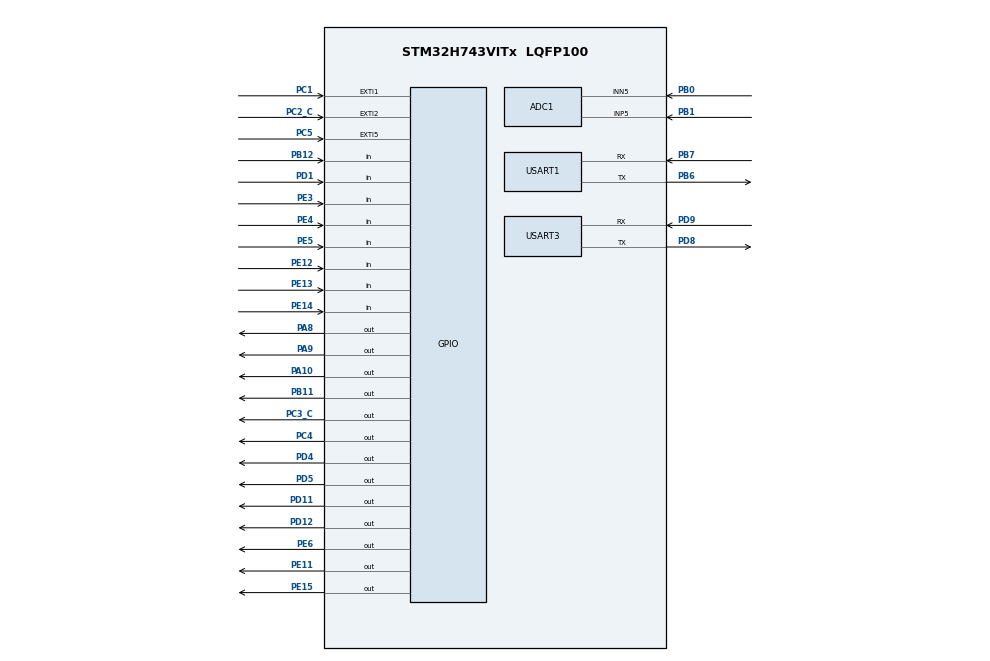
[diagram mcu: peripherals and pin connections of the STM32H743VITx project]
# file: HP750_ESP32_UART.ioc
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ADC1.Channel-1\#ChannelRegularConversion=ADC_CHANNEL_5
ADC1.NbrOfConversionFlag=1
ADC1.OffsetNumber-1\#ChannelRegularConversion=ADC_OFFSET_NONE
ADC1.OffsetSignedSaturation-1\#ChannelRegularConversion=DISABLE
ADC1.Rank-1\#ChannelRegularConversion=1
ADC1.SamplingTime-1\#ChannelRegularConversion=ADC_SAMPLETIME_1CYCLE_5
ADC1.SingleDiff-1\#ChannelRegularConversion=ADC_DIFFERENTIAL_ENDED
ADC1.master=1
Dma.Request0=USART3_RX
Dma.Request1=USART1_RX
Dma.USART1_RX.1.Direction=DMA_PERIPH_TO_MEMORY
Dma.USART1_RX.1.EventEnable=DISABLE
Dma.USART1_RX.1.FIFOMode=DMA_FIFOMODE_DISABLE
Dma.USART1_RX.1.Instance=DMA1_Stream1
Dma.USART1_RX.1.MemDataAlignment=DMA_MDATAALIGN_BYTE
Dma.USART1_RX.1.MemInc=DMA_MINC_ENABLE
Dma.USART1_RX.1.Mode=DMA_NORMAL
Dma.USART1_RX.1.PeriphDataAlignment=DMA_PDATAALIGN_BYTE
Dma.USART1_RX.1.PeriphInc=DMA_PINC_DISABLE
Dma.USART1_RX.1.Polarity=HAL_DMAMUX_REQ_GEN_RISING
Dma.USART1_RX.1.Priority=DMA_PRIORITY_LOW
Dma.USART1_RX.1.RequestNumber=1
Dma.USART1_RX.1.SignalID=NONE
Dma.USART1_RX.1.SyncEnable=DISABLE
Dma.USART1_RX.1.SyncPolarity=HAL_DMAMUX_SYNC_NO_EVENT
Dma.USART1_RX.1.SyncRequestNumber=1
Dma.USART1_RX.1.SyncSignalID=NONE
Dma.USART3_RX.0.Direction=DMA_PERIPH_TO_MEMORY
Dma.USART3_RX.0.EventEnable=DISABLE
Dma.USART3_RX.0.FIFOMode=DMA_FIFOMODE_DISABLE
Dma.USART3_RX.0.Instance=DMA1_Stream0
Dma.USART3_RX.0.MemDataAlignment=DMA_MDATAALIGN_BYTE
Dma.USART3_RX.0.MemInc=DMA_MINC_ENABLE
Dma.USART3_RX.0.Mode=DMA_NORMAL
Dma.USART3_RX.0.PeriphDataAlignment=DMA_PDATAALIGN_BYTE
Dma.USART3_RX.0.PeriphInc=DMA_PINC_DISABLE
Dma.USART3_RX.0.Polarity=HAL_DMAMUX_REQ_GEN_RISING
Dma.USART3_RX.0.Priority=DMA_PRIORITY_LOW
Dma.USART3_RX.0.RequestNumber=1
Dma.USART3_RX.0.SignalID=NONE
Dma.USART3_RX.0.SyncEnable=DISABLE
Dma.USART3_RX.0.SyncPolarity=HAL_DMAMUX_SYNC_NO_EVENT
Dma.USART3_RX.0.SyncRequestNumber=1
Dma.USART3_RX.0.SyncSignalID=NONE
Mcu.Family=STM32H7
Mcu.Name=STM32H743VITx
Mcu.Package=LQFP100
NVIC.DMA1_Stream0_IRQn=true\:0\:0\:false\:false\:true\:false\:true\:true
NVIC.DMA1_Stream1_IRQn=true\:0\:0\:false\:false\:true\:false\:true\:true
NVIC.PriorityGroup=NVIC_PRIORITYGROUP_4
NVIC.TIM1_UP_IRQn=true\:15\:0\:false\:false\:true\:false\:true\:true
NVIC.TimeBase=TIM1_UP_IRQn
NVIC.TimeBaseIP=TIM1
PA10.Signal=GPIO_Output
PA13\ (JTMS/SWDIO).Mode=Serial_Wire
PA13\ (JTMS/SWDIO).Signal=DEBUG_JTMS-SWDIO
PA14\ (JTCK/SWCLK).Mode=Serial_Wire
PA14\ (JTCK/SWCLK).Signal=DEBUG_JTCK-SWCLK
PA8.Signal=GPIO_Output
PA9.Signal=GPIO_Output
PB0.Signal=ADCx_INN5
PB1.Signal=ADCx_INP5
PB11.Signal=GPIO_Output
PB12.Signal=GPIO_Input
PB6.Mode=Asynchronous
PB6.Signal=USART1_TX
PB7.Mode=Asynchronous
PB7.Signal=USART1_RX
PC1.Signal=GPXTI1
PC14-OSC32_IN\ (OSC32_IN).Mode=LSE-External-Oscillator
PC14-OSC32_IN\ (OSC32_IN).Signal=RCC_OSC32_IN
PC15-OSC32_OUT\ (OSC32_OUT).Mode=LSE-External-Oscillator
PC15-OSC32_OUT\ (OSC32_OUT).Signal=RCC_OSC32_OUT
PC2_C.Signal=GPXTI2
PC3_C.Signal=GPIO_Output
PC4.Signal=GPIO_Output
PC5.Signal=GPXTI5
PD1.Signal=GPIO_Input
PD11.Signal=GPIO_Output
PD12.GPIO_PuPd=GPIO_NOPULL
PD12.Signal=GPIO_Output
PD4.Signal=GPIO_Output
PD5.Signal=GPIO_Output
PD8.Mode=Asynchronous
PD8.Signal=USART3_TX
PD9.Mode=Asynchronous
PD9.Signal=USART3_RX
PE11.Signal=GPIO_Output
PE12.Signal=GPIO_Input
PE13.Signal=GPIO_Input
PE14.Signal=GPIO_Input
PE15.Signal=GPIO_Output
PE3.Signal=GPIO_Input
PE4.Signal=GPIO_Input
PE5.Signal=GPIO_Input
PE6.Signal=GPIO_Output
PH0-OSC_IN\ (PH0).Mode=HSE-External-Oscillator
PH0-OSC_IN\ (PH0).Signal=RCC_OSC_IN
PH1-OSC_OUT\ (PH1).Mode=HSE-External-Oscillator
PH1-OSC_OUT\ (PH1).Signal=RCC_OSC_OUT
ProjectManager.HeapSize=0x200
ProjectManager.StackSize=0x400
ProjectManager.TargetToolchain=STM32CubeIDE
RCC.ADCFreq_Value=37500000
RCC.APB1Freq_Value=32000000
RCC.APB2Freq_Value=32000000
RCC.APB3Freq_Value=64000000
RCC.APB4Freq_Value=64000000
RCC.CortexFreq_Value=64000000
RCC.D2PPRE1=RCC_APB1_DIV2
RCC.D2PPRE2=RCC_APB2_DIV2
RCC.DIVM1=1
RCC.DIVM2=1
RCC.DIVN1=12
RCC.DIVN2=9
RCC.DIVP2=4
RCC.DIVQ1=4
RCC.HCLKFreq_Value=64000000
RCC.HSE_VALUE=16000000
RCC.PLL2FRACN=3072
RCC.PLLFRACN=0
RCC.PLLSourceVirtual=RCC_PLLSOURCE_HSE
RCC.SYSCLKFreq_VALUE=64000000
RCC.USBFreq_Value=48000000
SH.ADCx_INN5.0=ADC1_INN5,IN5-Differential
SH.ADCx_INP5.0=ADC1_INP5,IN5-Differential
USART1.VirtualMode-Asynchronous=VM_ASYNC
USART3.VirtualMode-Asynchronous=VM_ASYNC
VP_SYS_VS_tim1.Mode=TIM1
board=custom

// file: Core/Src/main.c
/* USER CODE BEGIN Header */
/**
  ******************************************************************************
  * @file           : main.c
  * @brief          : Main program body
  ******************************************************************************
  * @attention
  *
  * Copyright (c) 2023 STMicroelectronics.
  * All rights reserved.
  *
  * This software is licensed under terms that can be found in the LICENSE file
  * in the root directory of this software component.
  * If no LICENSE file comes with this software, it is provided AS-IS.
  *
  ******************************************************************************
  */
/* USER CODE END Header */
#include "main.h"

/* USER CODE BEGIN Includes */
#include "uart.h"
/* USER CODE END Includes */

ADC_HandleTypeDef hadc1;

UART_HandleTypeDef huart1;
UART_HandleTypeDef huart3;
DMA_HandleTypeDef hdma_usart1_rx;
DMA_HandleTypeDef hdma_usart3_rx;

void SystemClock_Config(void);
static void MX_GPIO_Init(void);
static void MX_DMA_Init(void);
static void MX_ADC1_Init(void);
static void MX_USART1_UART_Init(void);
static void MX_USART3_UART_Init(void);

int main(void)
{

  /* MCU Configuration--------------------------------------------------------*/

  /* Reset of all peripherals, Initializes the Flash interface and the Systick. */
  HAL_Init();

  /* Configure the system clock */
  SystemClock_Config();

  /* Initialize all configured peripherals */
  MX_GPIO_Init();
  MX_DMA_Init();
  MX_ADC1_Init();
  MX_USART1_UART_Init();
  MX_USART3_UART_Init();
  /* USER CODE BEGIN 2 */
  HAL_GPIO_WritePin(GPIOD, GPIO_PIN_12, GPIO_PIN_SET);
  HAL_GPIO_WritePin(GPIOD, GPIO_PIN_11, GPIO_PIN_SET);
  HAL_Delay(500);
  InitUartQueue(&WifiQueue);
  InitUartQueue(&MonitorQueue);
  if (HAL_UART_Receive_DMA(&hWifi, WifiQueue.Buffer, 1) != HAL_OK)
   {
     Error_Handler();
   }
   if (HAL_UART_Receive_DMA(&hMonitor, MonitorQueue.Buffer, 1) != HAL_OK)
   {
     Error_Handler();
   }
  /* USER CODE END 2 */

  /* Infinite loop */
  /* USER CODE BEGIN WHILE */
 //  InitUartQueue(&WifiQueue);

  while (1)
  {

    /* USER CODE END WHILE */

    /* USER CODE BEGIN 3 */
	    while (WifiQueue.data > 0) GetDataFromUartQueue(&hWifi);
	    while (MonitorQueue.data > 0) GetDataFromUartQueue(&hMonitor);
  }
  /* USER CODE END 3 */
}

void SystemClock_Config(void)
{
  RCC_OscInitTypeDef RCC_OscInitStruct = {0};
  RCC_ClkInitTypeDef RCC_ClkInitStruct = {0};

  /** Supply configuration update enable
  */
  HAL_PWREx_ConfigSupply(PWR_LDO_SUPPLY);

  /** Configure the main internal regulator output voltage
  */
  __HAL_PWR_VOLTAGESCALING_CONFIG(PWR_REGULATOR_VOLTAGE_SCALE3);

  while(!__HAL_PWR_GET_FLAG(PWR_FLAG_VOSRDY)) {}

  /** Macro to configure the PLL clock source
  */
  __HAL_RCC_PLL_PLLSOURCE_CONFIG(RCC_PLLSOURCE_HSE);

  /** Initializes the RCC Oscillators according to the specified parameters
  * in the RCC_OscInitTypeDef structure.
  */
  RCC_OscInitStruct.OscillatorType = RCC_OSCILLATORTYPE_HSI|RCC_OSCILLATORTYPE_HSE;
  RCC_OscInitStruct.HSEState = RCC_HSE_ON;
  RCC_OscInitStruct.HSIState = RCC_HSI_DIV1;
  RCC_OscInitStruct.HSICalibrationValue = RCC_HSICALIBRATION_DEFAULT;
  RCC_OscInitStruct.PLL.PLLState = RCC_PLL_NONE;
  if (HAL_RCC_OscConfig(&RCC_OscInitStruct) != HAL_OK)
  {
    Error_Handler();
  }

  /** Initializes the CPU, AHB and APB buses clocks
  */
  RCC_ClkInitStruct.ClockType = RCC_CLOCKTYPE_HCLK|RCC_CLOCKTYPE_SYSCLK
                              |RCC_CLOCKTYPE_PCLK1|RCC_CLOCKTYPE_PCLK2
                              |RCC_CLOCKTYPE_D3PCLK1|RCC_CLOCKTYPE_D1PCLK1;
  RCC_ClkInitStruct.SYSCLKSource = RCC_SYSCLKSOURCE_HSI;
  RCC_ClkInitStruct.SYSCLKDivider = RCC_SYSCLK_DIV1;
  RCC_ClkInitStruct.AHBCLKDivider = RCC_HCLK_DIV1;
  RCC_ClkInitStruct.APB3CLKDivider = RCC_APB3_DIV1;
  RCC_ClkInitStruct.APB1CLKDivider = RCC_APB1_DIV2;
  RCC_ClkInitStruct.APB2CLKDivider = RCC_APB2_DIV2;
  RCC_ClkInitStruct.APB4CLKDivider = RCC_APB4_DIV1;

  if (HAL_RCC_ClockConfig(&RCC_ClkInitStruct, FLASH_LATENCY_1) != HAL_OK)
  {
    Error_Handler();
  }
}

static void MX_ADC1_Init(void)
{

  ADC_MultiModeTypeDef multimode = {0};
  ADC_ChannelConfTypeDef sConfig = {0};

  /** Common config
  */
  hadc1.Instance = ADC1;
  hadc1.Init.ClockPrescaler = ADC_CLOCK_ASYNC_DIV1;
  hadc1.Init.Resolution = ADC_RESOLUTION_16B;
  hadc1.Init.ScanConvMode = ADC_SCAN_DISABLE;
  hadc1.Init.EOCSelection = ADC_EOC_SINGLE_CONV;
  hadc1.Init.LowPowerAutoWait = DISABLE;
  hadc1.Init.ContinuousConvMode = DISABLE;
  hadc1.Init.NbrOfConversion = 1;
  hadc1.Init.DiscontinuousConvMode = DISABLE;
  hadc1.Init.ExternalTrigConv = ADC_SOFTWARE_START;
  hadc1.Init.ExternalTrigConvEdge = ADC_EXTERNALTRIGCONVEDGE_NONE;
  hadc1.Init.ConversionDataManagement = ADC_CONVERSIONDATA_DR;
  hadc1.Init.Overrun = ADC_OVR_DATA_PRESERVED;
  hadc1.Init.LeftBitShift = ADC_LEFTBITSHIFT_NONE;
  hadc1.Init.OversamplingMode = DISABLE;
  if (HAL_ADC_Init(&hadc1) != HAL_OK)
  {
    Error_Handler();
  }

  /** Configure the ADC multi-mode
  */
  multimode.Mode = ADC_MODE_INDEPENDENT;
  if (HAL_ADCEx_MultiModeConfigChannel(&hadc1, &multimode) != HAL_OK)
  {
    Error_Handler();
  }

  /** Configure Regular Channel
  */
  sConfig.Channel = ADC_CHANNEL_5;
  sConfig.Rank = ADC_REGULAR_RANK_1;
  sConfig.SamplingTime = ADC_SAMPLETIME_1CYCLE_5;
  sConfig.SingleDiff = ADC_DIFFERENTIAL_ENDED;
  sConfig.OffsetNumber = ADC_OFFSET_NONE;
  sConfig.Offset = 0;
  sConfig.OffsetSignedSaturation = DISABLE;
  if (HAL_ADC_ConfigChannel(&hadc1, &sConfig) != HAL_OK)
  {
    Error_Handler();
  }

}

static void MX_USART1_UART_Init(void)
{

  huart1.Instance = USART1;
  huart1.Init.BaudRate = 115200;
  huart1.Init.WordLength = UART_WORDLENGTH_8B;
  huart1.Init.StopBits = UART_STOPBITS_1;
  huart1.Init.Parity = UART_PARITY_NONE;
  huart1.Init.Mode = UART_MODE_TX_RX;
  huart1.Init.HwFlowCtl = UART_HWCONTROL_NONE;
  huart1.Init.OverSampling = UART_OVERSAMPLING_16;
  huart1.Init.OneBitSampling = UART_ONE_BIT_SAMPLE_DISABLE;
  huart1.Init.ClockPrescaler = UART_PRESCALER_DIV1;
  huart1.AdvancedInit.AdvFeatureInit = UART_ADVFEATURE_NO_INIT;
  if (HAL_UART_Init(&huart1) != HAL_OK)
  {
    Error_Handler();
  }
  if (HAL_UARTEx_SetTxFifoThreshold(&huart1, UART_TXFIFO_THRESHOLD_1_8) != HAL_OK)
  {
    Error_Handler();
  }
  if (HAL_UARTEx_SetRxFifoThreshold(&huart1, UART_RXFIFO_THRESHOLD_1_8) != HAL_OK)
  {
    Error_Handler();
  }
  if (HAL_UARTEx_DisableFifoMode(&huart1) != HAL_OK)
  {
    Error_Handler();
  }

}

static void MX_USART3_UART_Init(void)
{

  huart3.Instance = USART3;
  huart3.Init.BaudRate = 115200;
  huart3.Init.WordLength = UART_WORDLENGTH_8B;
  huart3.Init.StopBits = UART_STOPBITS_1;
  huart3.Init.Parity = UART_PARITY_NONE;
  huart3.Init.Mode = UART_MODE_TX_RX;
  huart3.Init.HwFlowCtl = UART_HWCONTROL_NONE;
  huart3.Init.OverSampling = UART_OVERSAMPLING_16;
  huart3.Init.OneBitSampling = UART_ONE_BIT_SAMPLE_DISABLE;
  huart3.Init.ClockPrescaler = UART_PRESCALER_DIV1;
  huart3.AdvancedInit.AdvFeatureInit = UART_ADVFEATURE_NO_INIT;
  if (HAL_UART_Init(&huart3) != HAL_OK)
  {
    Error_Handler();
  }
  if (HAL_UARTEx_SetTxFifoThreshold(&huart3, UART_TXFIFO_THRESHOLD_1_8) != HAL_OK)
  {
    Error_Handler();
  }
  if (HAL_UARTEx_SetRxFifoThreshold(&huart3, UART_RXFIFO_THRESHOLD_1_8) != HAL_OK)
  {
    Error_Handler();
  }
  if (HAL_UARTEx_DisableFifoMode(&huart3) != HAL_OK)
  {
    Error_Handler();
  }

}

static void MX_DMA_Init(void)
{

  /* DMA controller clock enable */
  __HAL_RCC_DMA1_CLK_ENABLE();

  /* DMA interrupt init */
  /* DMA1_Stream0_IRQn interrupt configuration */
  HAL_NVIC_SetPriority(DMA1_Stream0_IRQn, 0, 0);
  HAL_NVIC_EnableIRQ(DMA1_Stream0_IRQn);
  /* DMA1_Stream1_IRQn interrupt configuration */
  HAL_NVIC_SetPriority(DMA1_Stream1_IRQn, 0, 0);
  HAL_NVIC_EnableIRQ(DMA1_Stream1_IRQn);

}

static void MX_GPIO_Init(void)
{
  GPIO_InitTypeDef GPIO_InitStruct = {0};

  /* GPIO Ports Clock Enable */
  __HAL_RCC_GPIOE_CLK_ENABLE();
  __HAL_RCC_GPIOC_CLK_ENABLE();
  __HAL_RCC_GPIOH_CLK_ENABLE();
  __HAL_RCC_GPIOB_CLK_ENABLE();
  __HAL_RCC_GPIOD_CLK_ENABLE();
  __HAL_RCC_GPIOA_CLK_ENABLE();

  /*Configure GPIO pin Output Level */
  HAL_GPIO_WritePin(GPIOE, GPIO_PIN_6|GPIO_PIN_11|GPIO_PIN_15, GPIO_PIN_RESET);

  /*Configure GPIO pin Output Level */
  HAL_GPIO_WritePin(GPIOC, GPIO_PIN_3|GPIO_PIN_4, GPIO_PIN_RESET);

  /*Configure GPIO pin Output Level */
  HAL_GPIO_WritePin(GPIOB, GPIO_PIN_11, GPIO_PIN_RESET);

  /*Configure GPIO pin Output Level */
  HAL_GPIO_WritePin(GPIOD, GPIO_PIN_11|GPIO_PIN_12|GPIO_PIN_4|GPIO_PIN_5, GPIO_PIN_RESET);

  /*Configure GPIO pin Output Level */
  HAL_GPIO_WritePin(GPIOA, GPIO_PIN_8|GPIO_PIN_9|GPIO_PIN_10, GPIO_PIN_RESET);

  /*Configure GPIO pins : PE3 PE4 PE5 PE12
                           PE13 PE14 */
  GPIO_InitStruct.Pin = GPIO_PIN_3|GPIO_PIN_4|GPIO_PIN_5|GPIO_PIN_12
                          |GPIO_PIN_13|GPIO_PIN_14;
  GPIO_InitStruct.Mode = GPIO_MODE_INPUT;
  GPIO_InitStruct.Pull = GPIO_NOPULL;
  HAL_GPIO_Init(GPIOE, &GPIO_InitStruct);

  /*Configure GPIO pins : PE6 PE11 PE15 */
  GPIO_InitStruct.Pin = GPIO_PIN_6|GPIO_PIN_11|GPIO_PIN_15;
  GPIO_InitStruct.Mode = GPIO_MODE_OUTPUT_PP;
  GPIO_InitStruct.Pull = GPIO_NOPULL;
  GPIO_InitStruct.Speed = GPIO_SPEED_FREQ_LOW;
  HAL_GPIO_Init(GPIOE, &GPIO_InitStruct);

  /*Configure GPIO pins : PC1 PC2 PC5 */
  GPIO_InitStruct.Pin = GPIO_PIN_1|GPIO_PIN_2|GPIO_PIN_5;
  GPIO_InitStruct.Mode = GPIO_MODE_IT_RISING;
  GPIO_InitStruct.Pull = GPIO_NOPULL;
  HAL_GPIO_Init(GPIOC, &GPIO_InitStruct);

  /*Configure GPIO pins : PC3 PC4 */
  GPIO_InitStruct.Pin = GPIO_PIN_3|GPIO_PIN_4;
  GPIO_InitStruct.Mode = GPIO_MODE_OUTPUT_PP;
  GPIO_InitStruct.Pull = GPIO_NOPULL;
  GPIO_InitStruct.Speed = GPIO_SPEED_FREQ_LOW;
  HAL_GPIO_Init(GPIOC, &GPIO_InitStruct);

  /*Configure GPIO pin : PB11 */
  GPIO_InitStruct.Pin = GPIO_PIN_11;
  GPIO_InitStruct.Mode = GPIO_MODE_OUTPUT_PP;
  GPIO_InitStruct.Pull = GPIO_NOPULL;
  GPIO_InitStruct.Speed = GPIO_SPEED_FREQ_LOW;
  HAL_GPIO_Init(GPIOB, &GPIO_InitStruct);

  /*Configure GPIO pin : PB12 */
  GPIO_InitStruct.Pin = GPIO_PIN_12;
  GPIO_InitStruct.Mode = GPIO_MODE_INPUT;
  GPIO_InitStruct.Pull = GPIO_NOPULL;
  HAL_GPIO_Init(GPIOB, &GPIO_InitStruct);

  /*Configure GPIO pins : PD11 PD12 PD4 PD5 */
  GPIO_InitStruct.Pin = GPIO_PIN_11|GPIO_PIN_12|GPIO_PIN_4|GPIO_PIN_5;
  GPIO_InitStruct.Mode = GPIO_MODE_OUTPUT_PP;
  GPIO_InitStruct.Pull = GPIO_NOPULL;
  GPIO_InitStruct.Speed = GPIO_SPEED_FREQ_LOW;
  HAL_GPIO_Init(GPIOD, &GPIO_InitStruct);

  /*Configure GPIO pins : PA8 PA9 PA10 */
  GPIO_InitStruct.Pin = GPIO_PIN_8|GPIO_PIN_9|GPIO_PIN_10;
  GPIO_InitStruct.Mode = GPIO_MODE_OUTPUT_PP;
  GPIO_InitStruct.Pull = GPIO_NOPULL;
  GPIO_InitStruct.Speed = GPIO_SPEED_FREQ_LOW;
  HAL_GPIO_Init(GPIOA, &GPIO_InitStruct);

  /*Configure GPIO pin : PD1 */
  GPIO_InitStruct.Pin = GPIO_PIN_1;
  GPIO_InitStruct.Mode = GPIO_MODE_INPUT;
  GPIO_InitStruct.Pull = GPIO_NOPULL;
  HAL_GPIO_Init(GPIOD, &GPIO_InitStruct);

}

void HAL_TIM_PeriodElapsedCallback(TIM_HandleTypeDef *htim)
{
  if (htim->Instance == TIM1) {
    HAL_IncTick();
  }
}

void Error_Handler(void)
{
  __disable_irq();
  while (1)
  {
  }
}
